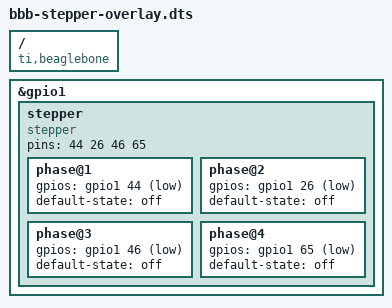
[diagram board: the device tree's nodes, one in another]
/dts-v1/;
/plugin/;

/ {
	compatible = "ti,beaglebone", "ti,beaglebone-black";

	fragment@0 {
		target = <&gpio1>;
		__overlay__ {
			stepper: stepper {
				compatible = "stepper";
				pins = <44 26 46 65>;
				phase@1 {
					gpios = <&gpio1 44 GPIO_ACTIVE_LOW>;
					default-state = "off";
				};
				phase@2 {
					gpios = <&gpio1 26 GPIO_ACTIVE_LOW>;
					default-state = "off";
				};
				phase@3 {
					gpios = <&gpio1 46 GPIO_ACTIVE_LOW>;
					default-state = "off";
				};
				phase@4 {
					gpios = <&gpio1 65 GPIO_ACTIVE_LOW>;
					default-state = "off";
				};
			};
		};
	};
};
